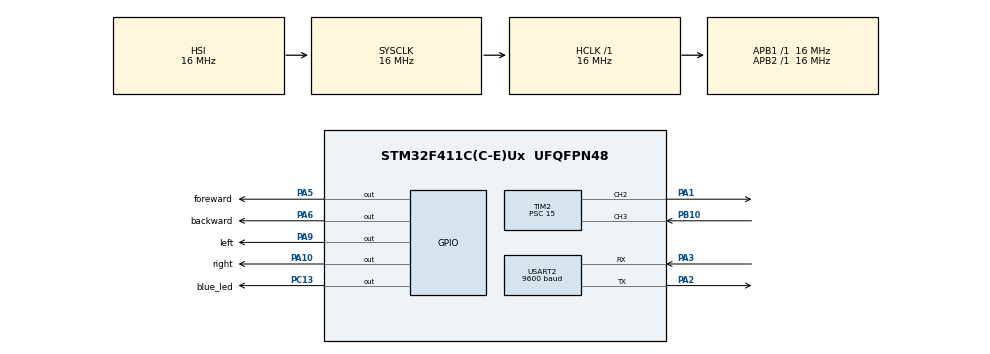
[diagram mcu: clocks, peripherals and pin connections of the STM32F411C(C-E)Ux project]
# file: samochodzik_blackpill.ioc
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Mcu.Family=STM32F4
Mcu.Name=STM32F411C(C-E)Ux
Mcu.Package=UFQFPN48
NVIC.PriorityGroup=NVIC_PRIORITYGROUP_4
NVIC.TIM2_IRQn=true\:0\:0\:false\:false\:true\:true\:true\:true
NVIC.USART2_IRQn=true\:0\:0\:false\:false\:true\:true\:true\:true
PA1.Signal=S_TIM2_CH2
PA10.GPIO_Label=right
PA10.Signal=GPIO_Output
PA2.Mode=Asynchronous
PA2.Signal=USART2_TX
PA3.Mode=Asynchronous
PA3.Signal=USART2_RX
PA5.GPIO_Label=foreward
PA5.Signal=GPIO_Output
PA6.GPIO_Label=backward
PA6.Signal=GPIO_Output
PA9.GPIO_Label=left
PA9.Signal=GPIO_Output
PB10.Signal=S_TIM2_CH3
PC13-ANTI_TAMP.GPIO_Label=blue_led
PC13-ANTI_TAMP.Signal=GPIO_Output
PH0\ -\ OSC_IN.Mode=HSE-External-Oscillator
PH0\ -\ OSC_IN.Signal=RCC_OSC_IN
PH1\ -\ OSC_OUT.Mode=HSE-External-Oscillator
PH1\ -\ OSC_OUT.Signal=RCC_OSC_OUT
ProjectManager.HeapSize=0x200
ProjectManager.StackSize=0x400
ProjectManager.TargetToolchain=STM32CubeIDE
RCC.48MHZClocksFreq_Value=32000000
RCC.AHBFreq_Value=16000000
RCC.APB1Freq_Value=16000000
RCC.APB1TimFreq_Value=16000000
RCC.APB2Freq_Value=16000000
RCC.APB2TimFreq_Value=16000000
RCC.CortexFreq_Value=16000000
RCC.HCLKFreq_Value=16000000
RCC.HSE_VALUE=25000000
RCC.HSI_VALUE=16000000
RCC.LSE_VALUE=32768
RCC.PLLM=8
RCC.PLLN=64
RCC.SYSCLKFreq_VALUE=16000000
RCC.VCOOutputFreq_Value=128000000
SH.S_TIM2_CH2.0=TIM2_CH2,PWM Generation2 CH2
SH.S_TIM2_CH3.0=TIM2_CH3,Input_Capture3_from_TI3
TIM2.Channel-Input_Capture3_from_TI3=TIM_CHANNEL_3
TIM2.Channel-Input_Capture4_from_TI3_63=TIM_CHANNEL_4
TIM2.Channel-PWM\ Generation2\ CH2=TIM_CHANNEL_2
TIM2.ICPolarity_CH4=TIM_INPUTCHANNELPOLARITY_FALLING
TIM2.Period=250000-1
TIM2.Prescaler=15
TIM2.Pulse-PWM\ Generation2\ CH2=10
USART2.BaudRate=9600
USART2.VirtualMode=VM_ASYNC
VP_TIM2_VS_ClockSourceINT.Mode=Internal
VP_TIM2_VS_indirect_ch3.Mode=Input_Capture4_from_TI3_63
board=custom

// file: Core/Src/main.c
/* USER CODE BEGIN Header */
/**
  ******************************************************************************
  * @file           : main.c
  * @author         : Jacek Bielski
  * @author         : Jakub Wysocki
  * @brief          : Main program body of the application for PMIK project
  * @note The aim of the project is to remotely control a toy car using bluetooth,
  * This program was made as student project of the Warsaw University of Technology
  * as part of the PMIK subject (Programming microcontrollers)

  * @note In main function all peripherals are initialized, then program works on interupts from tim2 and usart2
  ******************************************************************************
  * @attention
  * This program is intendet to run on blackpill stm32f411
  * @attention
  * In order to properly run the program make sure that all crutial periphentials are enabled such as tim2, usart2,
  * Make sure that bluetooth.h, car_control.h, hc-sr04_read.h are included to main.h
  *
  ******************************************************************************
  */
/* USER CODE END Header */
#include "main.h"

TIM_HandleTypeDef htim2;

UART_HandleTypeDef huart2;

void SystemClock_Config(void);
static void MX_GPIO_Init(void);
static void MX_TIM2_Init(void);
static void MX_USART2_UART_Init(void);

/* USER CODE BEGIN 0 */

carStruct car = {200, 0, 0, 0};
uint8_t received = 0;
/* USER CODE END 0 */

int main(void)
{

  /* MCU Configuration--------------------------------------------------------*/

  /* Reset of all peripherals, Initializes the Flash interface and the Systick. */
  HAL_Init();

  /* Configure the system clock */
  SystemClock_Config();

  /* Initialize all configured peripherals */
  MX_GPIO_Init();
  MX_TIM2_Init();
  MX_USART2_UART_Init();

  /* Infinite loop */
  /* USER CODE BEGIN WHILE */
  HAL_TIM_Base_Start_IT(&htim2);
  hcsr04_read_init();
  car_init();
  HAL_Delay(1000);
  HAL_UART_Receive_IT(&huart2, &received, 1);

  while (1)
  {

    /* USER CODE END WHILE */

  }
}

void SystemClock_Config(void)
{
  RCC_OscInitTypeDef RCC_OscInitStruct = {0};
  RCC_ClkInitTypeDef RCC_ClkInitStruct = {0};

  /** Configure the main internal regulator output voltage
   */
  __HAL_RCC_PWR_CLK_ENABLE();
  __HAL_PWR_VOLTAGESCALING_CONFIG(PWR_REGULATOR_VOLTAGE_SCALE1);

  /** Initializes the RCC Oscillators according to the specified parameters
   * in the RCC_OscInitTypeDef structure.
   */
  RCC_OscInitStruct.OscillatorType = RCC_OSCILLATORTYPE_HSI;
  RCC_OscInitStruct.HSIState = RCC_HSI_ON;
  RCC_OscInitStruct.HSICalibrationValue = RCC_HSICALIBRATION_DEFAULT;
  RCC_OscInitStruct.PLL.PLLState = RCC_PLL_NONE;
  if (HAL_RCC_OscConfig(&RCC_OscInitStruct) != HAL_OK)
  {
    Error_Handler();
  }

  /** Initializes the CPU, AHB and APB buses clocks
   */
  RCC_ClkInitStruct.ClockType = RCC_CLOCKTYPE_HCLK | RCC_CLOCKTYPE_SYSCLK | RCC_CLOCKTYPE_PCLK1 | RCC_CLOCKTYPE_PCLK2;
  RCC_ClkInitStruct.SYSCLKSource = RCC_SYSCLKSOURCE_HSI;
  RCC_ClkInitStruct.AHBCLKDivider = RCC_SYSCLK_DIV1;
  RCC_ClkInitStruct.APB1CLKDivider = RCC_HCLK_DIV1;
  RCC_ClkInitStruct.APB2CLKDivider = RCC_HCLK_DIV1;

  if (HAL_RCC_ClockConfig(&RCC_ClkInitStruct, FLASH_LATENCY_0) != HAL_OK)
  {
    Error_Handler();
  }
}

static void MX_TIM2_Init(void)
{

  TIM_ClockConfigTypeDef sClockSourceConfig = {0};
  TIM_MasterConfigTypeDef sMasterConfig = {0};
  TIM_OC_InitTypeDef sConfigOC = {0};
  TIM_IC_InitTypeDef sConfigIC = {0};

  htim2.Instance = TIM2;
  htim2.Init.Prescaler = 15;
  htim2.Init.CounterMode = TIM_COUNTERMODE_UP;
  htim2.Init.Period = 250000 - 1;
  htim2.Init.ClockDivision = TIM_CLOCKDIVISION_DIV1;
  htim2.Init.AutoReloadPreload = TIM_AUTORELOAD_PRELOAD_DISABLE;
  if (HAL_TIM_Base_Init(&htim2) != HAL_OK)
  {
    Error_Handler();
  }
  sClockSourceConfig.ClockSource = TIM_CLOCKSOURCE_INTERNAL;
  if (HAL_TIM_ConfigClockSource(&htim2, &sClockSourceConfig) != HAL_OK)
  {
    Error_Handler();
  }
  if (HAL_TIM_PWM_Init(&htim2) != HAL_OK)
  {
    Error_Handler();
  }
  if (HAL_TIM_IC_Init(&htim2) != HAL_OK)
  {
    Error_Handler();
  }
  sMasterConfig.MasterOutputTrigger = TIM_TRGO_RESET;
  sMasterConfig.MasterSlaveMode = TIM_MASTERSLAVEMODE_DISABLE;
  if (HAL_TIMEx_MasterConfigSynchronization(&htim2, &sMasterConfig) != HAL_OK)
  {
    Error_Handler();
  }
  sConfigOC.OCMode = TIM_OCMODE_PWM1;
  sConfigOC.Pulse = 10;
  sConfigOC.OCPolarity = TIM_OCPOLARITY_HIGH;
  sConfigOC.OCFastMode = TIM_OCFAST_DISABLE;
  if (HAL_TIM_PWM_ConfigChannel(&htim2, &sConfigOC, TIM_CHANNEL_2) != HAL_OK)
  {
    Error_Handler();
  }
  sConfigIC.ICPolarity = TIM_INPUTCHANNELPOLARITY_RISING;
  sConfigIC.ICSelection = TIM_ICSELECTION_DIRECTTI;
  sConfigIC.ICPrescaler = TIM_ICPSC_DIV1;
  sConfigIC.ICFilter = 0;
  if (HAL_TIM_IC_ConfigChannel(&htim2, &sConfigIC, TIM_CHANNEL_3) != HAL_OK)
  {
    Error_Handler();
  }
  sConfigIC.ICPolarity = TIM_INPUTCHANNELPOLARITY_FALLING;
  sConfigIC.ICSelection = TIM_ICSELECTION_INDIRECTTI;
  if (HAL_TIM_IC_ConfigChannel(&htim2, &sConfigIC, TIM_CHANNEL_4) != HAL_OK)
  {
    Error_Handler();
  }
  HAL_TIM_MspPostInit(&htim2);
}

static void MX_USART2_UART_Init(void)
{

  huart2.Instance = USART2;
  huart2.Init.BaudRate = 9600;
  huart2.Init.WordLength = UART_WORDLENGTH_8B;
  huart2.Init.StopBits = UART_STOPBITS_1;
  huart2.Init.Parity = UART_PARITY_NONE;
  huart2.Init.Mode = UART_MODE_TX_RX;
  huart2.Init.HwFlowCtl = UART_HWCONTROL_NONE;
  huart2.Init.OverSampling = UART_OVERSAMPLING_16;
  if (HAL_UART_Init(&huart2) != HAL_OK)
  {
    Error_Handler();
  }
}

static void MX_GPIO_Init(void)
{
  GPIO_InitTypeDef GPIO_InitStruct = {0};

  /* GPIO Ports Clock Enable */
  __HAL_RCC_GPIOC_CLK_ENABLE();
  __HAL_RCC_GPIOH_CLK_ENABLE();
  __HAL_RCC_GPIOA_CLK_ENABLE();
  __HAL_RCC_GPIOB_CLK_ENABLE();

  /*Configure GPIO pin Output Level */
  HAL_GPIO_WritePin(blue_led_GPIO_Port, blue_led_Pin, GPIO_PIN_RESET);

  /*Configure GPIO pin Output Level */
  HAL_GPIO_WritePin(GPIOA, foreward_Pin | backward_Pin | left_Pin | right_Pin, GPIO_PIN_RESET);

  /*Configure GPIO pin : blue_led_Pin */
  GPIO_InitStruct.Pin = blue_led_Pin;
  GPIO_InitStruct.Mode = GPIO_MODE_OUTPUT_PP;
  GPIO_InitStruct.Pull = GPIO_NOPULL;
  GPIO_InitStruct.Speed = GPIO_SPEED_FREQ_LOW;
  HAL_GPIO_Init(blue_led_GPIO_Port, &GPIO_InitStruct);

  /*Configure GPIO pins : foreward_Pin backward_Pin left_Pin right_Pin */
  GPIO_InitStruct.Pin = foreward_Pin | backward_Pin | left_Pin | right_Pin;
  GPIO_InitStruct.Mode = GPIO_MODE_OUTPUT_PP;
  GPIO_InitStruct.Pull = GPIO_NOPULL;
  GPIO_InitStruct.Speed = GPIO_SPEED_FREQ_LOW;
  HAL_GPIO_Init(GPIOA, &GPIO_InitStruct);

}

void Error_Handler(void)
{
  __disable_irq();
  while (1)
  {
  }
}
